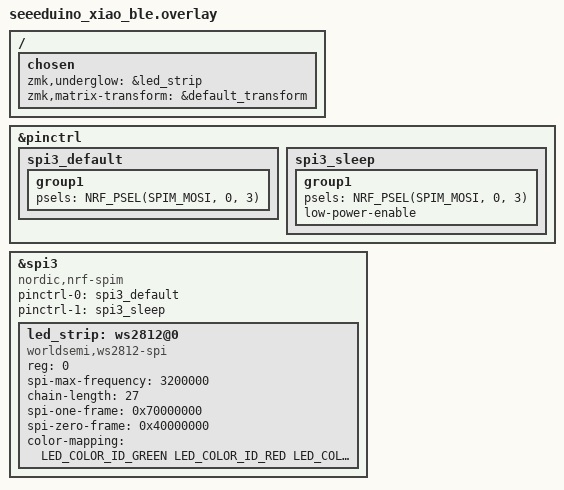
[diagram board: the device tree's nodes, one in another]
#include <dt-bindings/led/led.h>

/* XIAO nRF52840 P0.03 (D1ピン) を WS2812 データ出力に使用 */
&pinctrl {
    spi3_default: spi3_default {
        group1 {
            psels = <NRF_PSEL(SPIM_MOSI, 0, 3)>;
        };
    };

    spi3_sleep: spi3_sleep {
        group1 {
            psels = <NRF_PSEL(SPIM_MOSI, 0, 3)>;
            low-power-enable;
        };
    };
};

&spi3 {
    compatible = "nordic,nrf-spim";
    status = "okay";
    pinctrl-0 = <&spi3_default>;
    pinctrl-1 = <&spi3_sleep>;
    pinctrl-names = "default", "sleep";

    led_strip: ws2812@0 {
        compatible = "worldsemi,ws2812-spi";
        reg = <0>;
        spi-max-frequency = <3200000>;
        chain-length = <27>;           /* ← 実際のLED個数に合わせて変更 */
        spi-one-frame = <0x70000000>;
        spi-zero-frame = <0x40000000>;
        color-mapping = <LED_COLOR_ID_GREEN
                         LED_COLOR_ID_RED
                         LED_COLOR_ID_BLUE>;
    };
};

/* Underglow登録 */
/ {
    chosen {
        zmk,underglow = &led_strip;
        /* ここでPeripheral側と同じmatrix_transformを参照（新規定義なし） */
        zmk,matrix-transform = &default_transform;   /* ← あなたのキーボードの実際のラベルに変更してください */
    };
};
